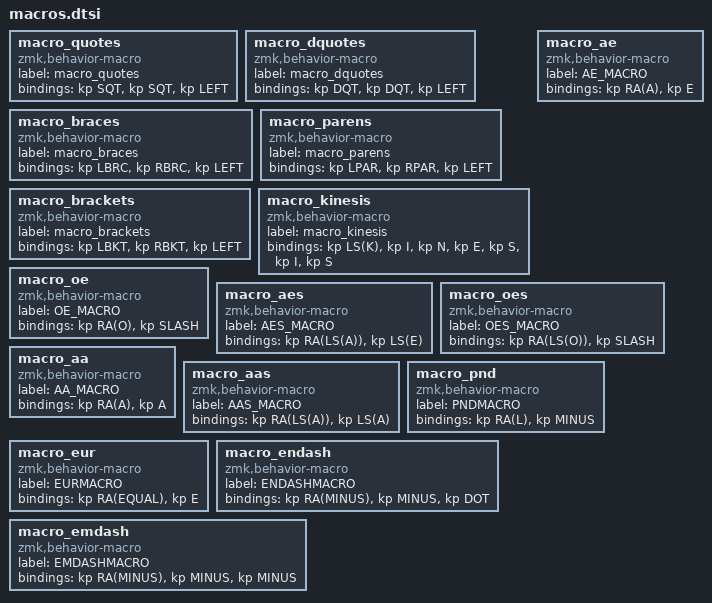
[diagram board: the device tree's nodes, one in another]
  macro_quotes: macro_quotes {
    compatible = "zmk,behavior-macro";
    label = "macro_quotes";
    #binding-cells = <0>;
    bindings = <&kp SQT>, <&kp SQT>, <&kp LEFT>;
  };
  macro_dquotes: macro_dquotes {
    compatible = "zmk,behavior-macro";
    label = "macro_dquotes";
    #binding-cells = <0>;
    bindings = <&kp DQT>, <&kp DQT>, <&kp LEFT>;
  };
  macro_braces: macro_braces {
    compatible = "zmk,behavior-macro";
    label = "macro_braces";
    #binding-cells = <0>;
    bindings = <&kp LBRC>, <&kp RBRC>, <&kp LEFT>;
  };
  macro_parens: macro_parens {
    compatible = "zmk,behavior-macro";
    label = "macro_parens";
    #binding-cells = <0>;
    bindings = <&kp LPAR>, <&kp RPAR>, <&kp LEFT>;
  };
  macro_brackets: macro_brackets {
    compatible = "zmk,behavior-macro";
    label = "macro_brackets";
    #binding-cells = <0>;
    bindings = <&kp LBKT>, <&kp RBKT>, <&kp LEFT>;
  };
  macro_kinesis: macro_kinesis {
    compatible = "zmk,behavior-macro";
    label = "macro_kinesis";
    #binding-cells = <0>;
    bindings = <&kp LS(K)>, <&kp I>, <&kp N>, <&kp E>, <&kp S>, <&kp I>, <&kp S>;
  };
  macro_ae: macro_ae {
        compatible = "zmk,behavior-macro";
        label = "AE_MACRO";
        #binding-cells = <0>;
        bindings = <&kp RA(A)>, <&kp E>;
  };
  macro_oe: macro_oe {
    compatible = "zmk,behavior-macro";
    label = "OE_MACRO";
    #binding-cells = <0>;
    bindings = <&kp RA(O)>, <&kp SLASH>;
  };

  macro_aes: macro_aes {
    compatible = "zmk,behavior-macro";
    label = "AES_MACRO";
    #binding-cells = <0>;
    bindings = <&kp RA(LS(A))>, <&kp LS(E)>;
  };

  macro_oes: macro_oes {
    compatible = "zmk,behavior-macro";
    label = "OES_MACRO";
    #binding-cells = <0>;
    bindings = <&kp RA(LS(O))>, <&kp SLASH>;
  };

  macro_aa: macro_aa {
    compatible = "zmk,behavior-macro";
    label = "AA_MACRO";
    #binding-cells = <0>;
    bindings = <&kp RA(A)>, <&kp A>;
  };

  macro_aas: macro_aas {
    compatible = "zmk,behavior-macro";
    label = "AAS_MACRO";
    #binding-cells = <0>;
    bindings = <&kp RA(LS(A))>, <&kp LS(A)>;
  };

  macro_pnd: macro_pnd {
    compatible = "zmk,behavior-macro";
    label = "PNDMACRO";
    #binding-cells = <0>;
    bindings = <&kp RA(L)>, <&kp MINUS>;
  };

  macro_eur: macro_eur {
    compatible = "zmk,behavior-macro";
    label = "EURMACRO";
    #binding-cells = <0>;
    bindings = <&kp RA(EQUAL)>, <&kp E>;
  };

  macro_endash: macro_endash {
    compatible = "zmk,behavior-macro";
    label = "ENDASHMACRO";
    #binding-cells = <0>;
    bindings = <&kp RA(MINUS)>, <&kp MINUS>, <&kp DOT>;
  };

  macro_emdash: macro_emdash {
    compatible = "zmk,behavior-macro";
    label = "EMDASHMACRO";
    #binding-cells = <0>;
    bindings = <&kp RA(MINUS)>, <&kp MINUS>, <&kp MINUS>;
  };
